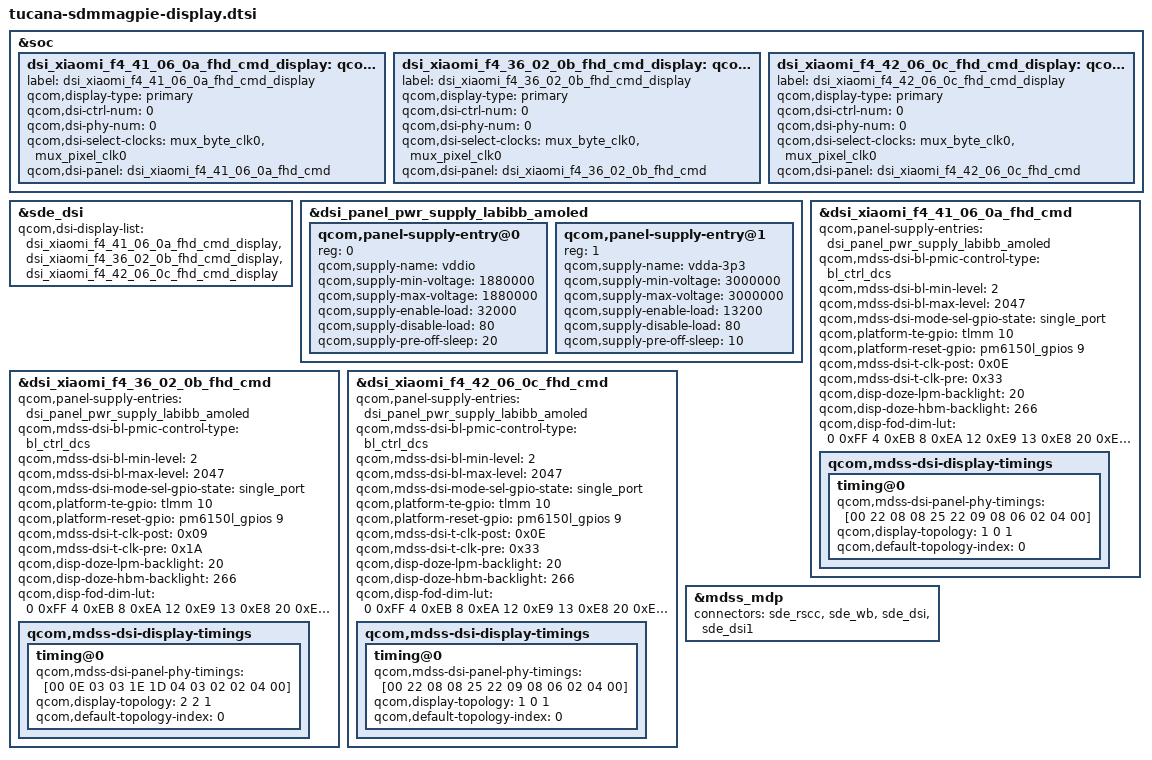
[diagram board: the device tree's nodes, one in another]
/*
 * Copyright (C) 2020 The LineageOS Project
 *
 * this file is for attribution only of tucana
 * And public attribution of Xiaomi platforms (like F4 and so)
 */
 
#include "../common/xiaomi-sdmmagpie-display.dtsi"

#include "display/dsi-panel-xiaomi-f4-36-02-0b-fhd-cmd.dtsi"
#include "display/dsi-panel-xiaomi-f4-41-06-0a-fhd-cmd.dtsi"
#include "display/dsi-panel-xiaomi-f4-42-06-0c-fhd-cmd.dtsi"

&soc {
    dsi_xiaomi_f4_41_06_0a_fhd_cmd_display: qcom,dsi-display@22 {
        label = "dsi_xiaomi_f4_41_06_0a_fhd_cmd_display";
        qcom,display-type = "primary";

        qcom,dsi-ctrl-num = <0>;
        qcom,dsi-phy-num = <0>;
        qcom,dsi-select-clocks = "mux_byte_clk0", "mux_pixel_clk0";

        qcom,dsi-panel = <&dsi_xiaomi_f4_41_06_0a_fhd_cmd>;
    };

    dsi_xiaomi_f4_36_02_0b_fhd_cmd_display: qcom,dsi-display@23 {
        label = "dsi_xiaomi_f4_36_02_0b_fhd_cmd_display";
        qcom,display-type = "primary";

        qcom,dsi-ctrl-num = <0>;
        qcom,dsi-phy-num = <0>;
        qcom,dsi-select-clocks = "mux_byte_clk0", "mux_pixel_clk0";

        qcom,dsi-panel = <&dsi_xiaomi_f4_36_02_0b_fhd_cmd>;
    };

    dsi_xiaomi_f4_42_06_0c_fhd_cmd_display: qcom,dsi-display@24 {
        label = "dsi_xiaomi_f4_42_06_0c_fhd_cmd_display";
        qcom,display-type = "primary";

        qcom,dsi-ctrl-num = <0>;
        qcom,dsi-phy-num = <0>;
        qcom,dsi-select-clocks = "mux_byte_clk0", "mux_pixel_clk0";

        qcom,dsi-panel = <&dsi_xiaomi_f4_42_06_0c_fhd_cmd>;
    };
};

&sde_dsi {
    qcom,dsi-display-list =
        <&dsi_xiaomi_f4_41_06_0a_fhd_cmd_display
        &dsi_xiaomi_f4_36_02_0b_fhd_cmd_display
        &dsi_xiaomi_f4_42_06_0c_fhd_cmd_display>;
};

&dsi_panel_pwr_supply_labibb_amoled {
	qcom,panel-supply-entry@0 {
		reg = <0>;
		qcom,supply-name = "vddio";
		qcom,supply-min-voltage = <1880000>;
		qcom,supply-max-voltage = <1880000>;
		qcom,supply-enable-load = <32000>;
		qcom,supply-disable-load = <80>;
		qcom,supply-pre-off-sleep = <20>;
	};
	qcom,panel-supply-entry@1 {
		reg = <1>;
		qcom,supply-name = "vdda-3p3";
		qcom,supply-min-voltage = <3000000>;
		qcom,supply-max-voltage = <3000000>;
		qcom,supply-enable-load = <13200>;
		qcom,supply-disable-load = <80>;
		qcom,supply-pre-off-sleep = <10>;
	};
};

&dsi_xiaomi_f4_41_06_0a_fhd_cmd {
	qcom,panel-supply-entries = <&dsi_panel_pwr_supply_labibb_amoled>;
	qcom,mdss-dsi-bl-pmic-control-type = "bl_ctrl_dcs";
	qcom,mdss-dsi-bl-min-level = <2>;
	qcom,mdss-dsi-bl-max-level = <2047>;
	qcom,mdss-dsi-mode-sel-gpio-state = "single_port";
	qcom,platform-te-gpio = <&tlmm 10 0>;
	qcom,platform-reset-gpio = <&pm6150l_gpios 9 0>;

	qcom,mdss-dsi-t-clk-post = <0x0E>;
	qcom,mdss-dsi-t-clk-pre = <0x33>;

	qcom,disp-doze-lpm-backlight = <20>;
	qcom,disp-doze-hbm-backlight = <266>;

	qcom,disp-fod-dim-lut = <
	  /* brightness, alpha */
	  0 0xFF
	  4 0xEB
	  8 0xEA
	  12  0xE9
	  13  0xE8
	  20  0xE5
	  24  0xE3
	  30  0xE0
	  68  0xD0
	  133 0xC0
	  218 0xB0
	  328 0xA0
	  486 0x90
	  642 0x80
	  832 0x70
	  1043  0x60
	  1267  0x50
	  1500  0x40
	  1770  0x30
	  2000  0x24
	  2047  0x21
	>;

	qcom,mdss-dsi-display-timings {
        timing@0{
            qcom,mdss-dsi-panel-phy-timings = [00 22 08 08 25 22 09
                08 06 02 04 00];
            qcom,display-topology = <1 0 1>;
            qcom,default-topology-index = <0>;
        };
    };
};

&dsi_xiaomi_f4_36_02_0b_fhd_cmd {
	qcom,panel-supply-entries = <&dsi_panel_pwr_supply_labibb_amoled>;
	qcom,mdss-dsi-bl-pmic-control-type = "bl_ctrl_dcs";
	qcom,mdss-dsi-bl-min-level = <2>;
	qcom,mdss-dsi-bl-max-level = <2047>;
	qcom,mdss-dsi-mode-sel-gpio-state = "single_port";
	qcom,platform-te-gpio = <&tlmm 10 0>;
	qcom,platform-reset-gpio = <&pm6150l_gpios 9 0>;

	qcom,mdss-dsi-t-clk-post = <0x09>;
	qcom,mdss-dsi-t-clk-pre = <0x1A>;

	qcom,disp-doze-lpm-backlight = <20>;
	qcom,disp-doze-hbm-backlight = <266>;

	qcom,disp-fod-dim-lut = <
	  /* brightness, alpha */
	  0 0xFF
	  4 0xEB
	  8 0xEA
	  12  0xE9
	  13  0xE8
	  20  0xE5
	  24  0xE3
	  30  0xE0
	  68  0xD0
	  133 0xC0
	  218 0xB0
	  328 0xA0
	  486 0x90
	  642 0x80
	  832 0x70
	  1043  0x60
	  1267  0x50
	  1500  0x40
	  1770  0x30
	  2000  0x24
	  2047  0x21
	>;

	qcom,mdss-dsi-display-timings {
	timing@0{
            qcom,mdss-dsi-panel-phy-timings = [00 0E 03 03 1E 1D 04
                03 02 02 04 00];
            qcom,display-topology = <2 2 1>;
            qcom,default-topology-index = <0>;
        };
    };
};

&dsi_xiaomi_f4_42_06_0c_fhd_cmd {
	qcom,panel-supply-entries = <&dsi_panel_pwr_supply_labibb_amoled>;
	qcom,mdss-dsi-bl-pmic-control-type = "bl_ctrl_dcs";
	qcom,mdss-dsi-bl-min-level = <2>;
	qcom,mdss-dsi-bl-max-level = <2047>;
	qcom,mdss-dsi-mode-sel-gpio-state = "single_port";
	qcom,platform-te-gpio = <&tlmm 10 0>;
	qcom,platform-reset-gpio = <&pm6150l_gpios 9 0>;

	qcom,mdss-dsi-t-clk-post = <0x0E>;
	qcom,mdss-dsi-t-clk-pre = <0x33>;

	qcom,disp-doze-lpm-backlight = <20>;
	qcom,disp-doze-hbm-backlight = <266>;

	qcom,disp-fod-dim-lut = <
	  /* brightness, alpha */
	  0 0xFF
	  4 0xEB
	  8 0xEA
	  12  0xE9
	  13  0xE8
	  20  0xE5
	  24  0xE3
	  30  0xE0
	  68  0xD0
	  133 0xC0
	  218 0xB0
	  328 0xA0
	  486 0x90
	  642 0x80
	  832 0x70
	  1043  0x60
	  1267  0x50
	  1500  0x40
	  1770  0x30
	  2000  0x24
	  2047  0x21
	>;

	qcom,mdss-dsi-display-timings {
        timing@0{
            qcom,mdss-dsi-panel-phy-timings = [00 22 08 08 25 22 09
                08 06 02 04 00];
            qcom,display-topology = <1 0 1>;
            qcom,default-topology-index = <0>;
        };
    };
};

&mdss_mdp {
	connectors = <&sde_rscc &sde_wb &sde_dsi &sde_dsi1>;
};
